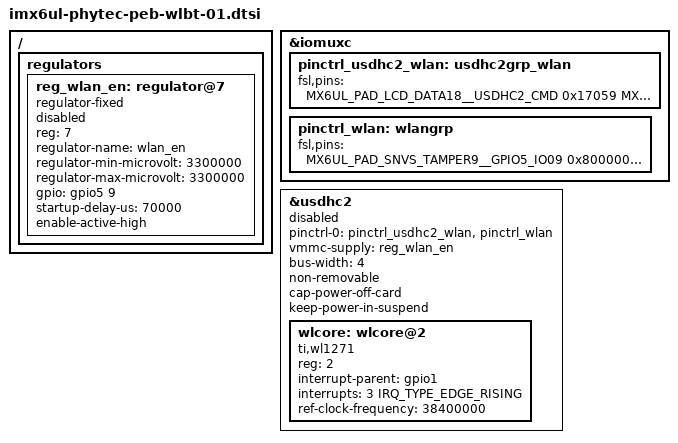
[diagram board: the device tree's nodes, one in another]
/*
 * The code contained herein is licensed under the GNU General Public
 * License. You may obtain a copy of the GNU General Public License
 * Version 2 or later at the following locations:
 *
 * http://www.opensource.org/licenses/gpl-license.html
 * http://www.gnu.org/copyleft/gpl.html
 */

#include <dt-bindings/gpio/gpio.h>
#include <dt-bindings/interrupt-controller/irq.h>

/ {
	regulators {
		reg_wlan_en: regulator@7 {
			compatible = "regulator-fixed";
			reg = <7>;
			regulator-name = "wlan_en";
			regulator-min-microvolt = <3300000>;
			regulator-max-microvolt = <3300000>;
			gpio = <&gpio5 9 GPIO_ACTIVE_HIGH>;
			startup-delay-us = <70000>; /* card specific delay */
			enable-active-high;
			status = "disabled";
		};
	};
};

&iomuxc {
	pinctrl_usdhc2_wlan: usdhc2grp_wlan {
		fsl,pins = <
			MX6UL_PAD_LCD_DATA18__USDHC2_CMD	0x17059
			MX6UL_PAD_LCD_DATA19__USDHC2_CLK	0x10059
			MX6UL_PAD_LCD_DATA20__USDHC2_DATA0	0x17059
			MX6UL_PAD_LCD_DATA21__USDHC2_DATA1	0x17059
			MX6UL_PAD_LCD_DATA22__USDHC2_DATA2	0x17059
			MX6UL_PAD_LCD_DATA23__USDHC2_DATA3	0x17059
		>;
	};

	pinctrl_wlan: wlangrp {
		fsl,pins = <
			/* WLAN ENABLE */
			MX6UL_PAD_SNVS_TAMPER9__GPIO5_IO09	0x80000000
			/* WLAN IRQ */
			MX6UL_PAD_GPIO1_IO03__GPIO1_IO03	0x80000000
		>;
	};
};

/* SDHC2 on phyBOARD-Segin i.MX6UL */
&usdhc2 {
	pinctrl-names = "default";
	pinctrl-0 = <&pinctrl_usdhc2_wlan &pinctrl_wlan>;
	vmmc-supply = <&reg_wlan_en>;
	bus-width = <4>;
	non-removable;
	cap-power-off-card;
	keep-power-in-suspend;
	status = "disabled";

	#address-cells = <1>;
	#size-cells = <0>;

	wlcore: wlcore@2 {
		compatible = "ti,wl1271";
		reg = <2>; /* WLAN function -> 2 */
		interrupt-parent = <&gpio1>;
		interrupts = <3 IRQ_TYPE_EDGE_RISING>;
		ref-clock-frequency = <38400000>; /* Hz = 38.4 MHz */
	};
};
